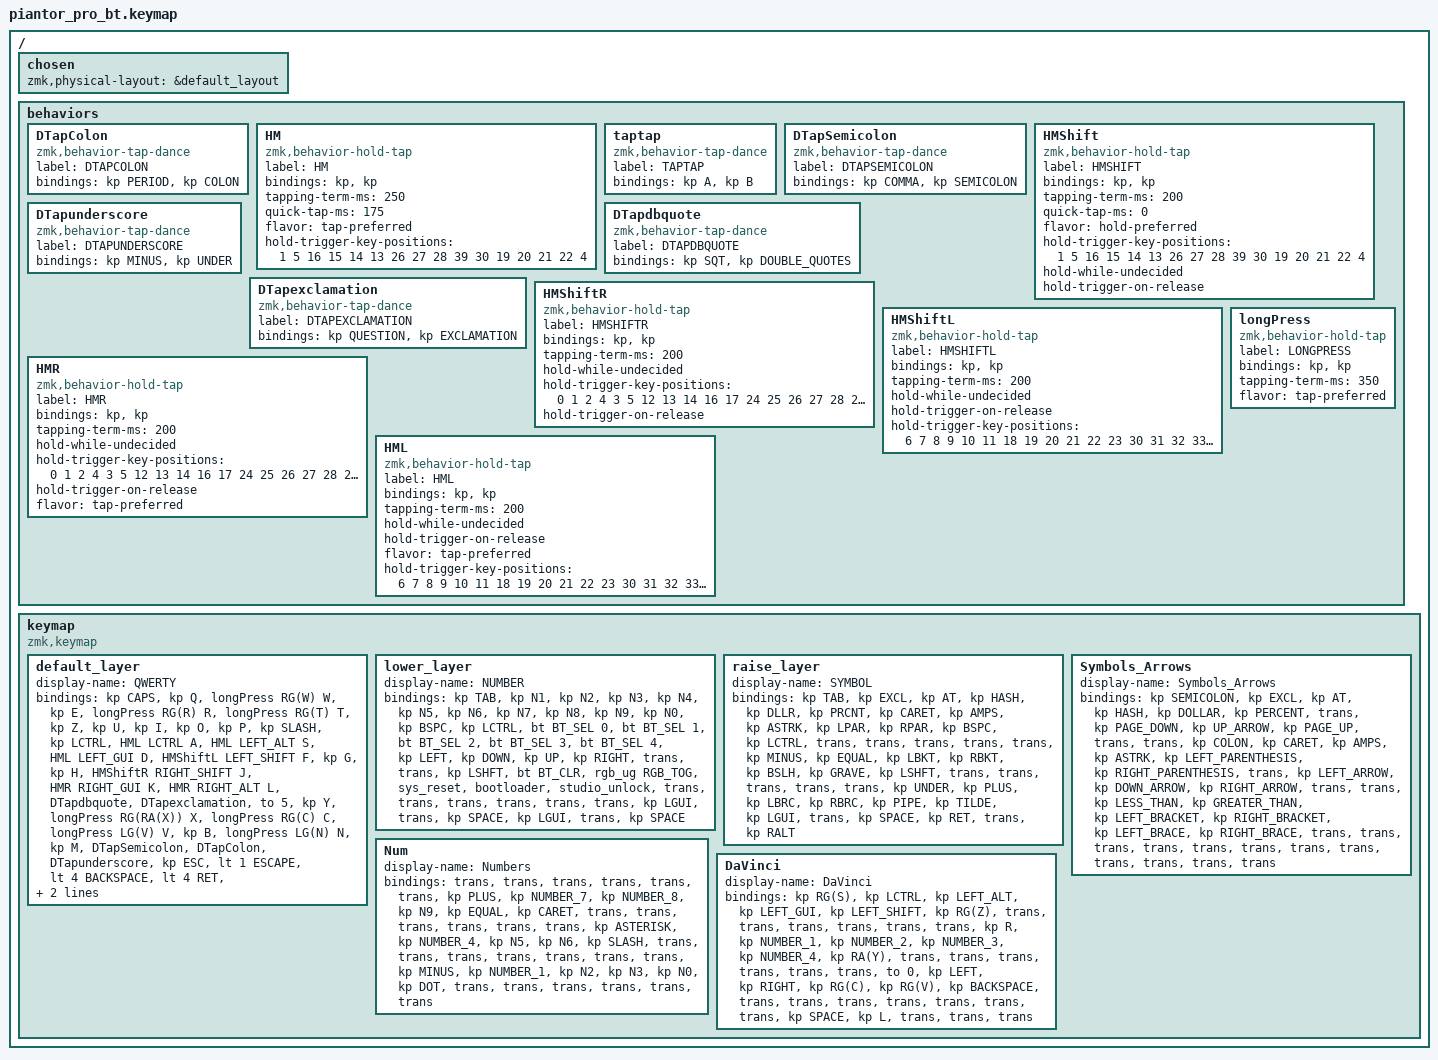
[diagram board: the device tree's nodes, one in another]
/*
 * Copyright (c) 2020 The ZMK Contributors
 *
 * SPDX-License-Identifier: MIT
 */

#include <behaviors.dtsi>
#include <dt-bindings/zmk/bt.h>
#include <dt-bindings/zmk/keys.h>
#include <dt-bindings/zmk/rgb.h>

/ {
    chosen { zmk,physical-layout = &default_layout; };
};

/ {
    behaviors {
        DTapColon: DTapColon {
            compatible = "zmk,behavior-tap-dance";
            label = "DTAPCOLON";
            #binding-cells = <0>;
            bindings = <&kp PERIOD>, <&kp COLON>;
        };

        HM: HM {
            compatible = "zmk,behavior-hold-tap";
            label = "HM";
            bindings = <&kp>, <&kp>;

            #binding-cells = <2>;
            tapping-term-ms = <250>;
            quick-tap-ms = <175>;
            flavor = "tap-preferred";
            hold-trigger-key-positions = <1 5 16 15 14 13 26 27 28 39 30 19 20 21 22 4>;
        };

        taptap: taptap {
            compatible = "zmk,behavior-tap-dance";
            label = "TAPTAP";
            #binding-cells = <0>;
            bindings = <&kp A>, <&kp B>;
        };

        DTapSemicolon: DTapSemicolon {
            compatible = "zmk,behavior-tap-dance";
            label = "DTAPSEMICOLON";
            #binding-cells = <0>;
            bindings = <&kp COMMA>, <&kp SEMICOLON>;
        };

        HMShift: HMShift {
            compatible = "zmk,behavior-hold-tap";
            label = "HMSHIFT";
            bindings = <&kp>, <&kp>;

            #binding-cells = <2>;
            tapping-term-ms = <200>;
            quick-tap-ms = <0>;
            flavor = "hold-preferred";
            hold-trigger-key-positions = <1 5 16 15 14 13 26 27 28 39 30 19 20 21 22 4>;
            hold-while-undecided;
            hold-trigger-on-release;
        };

        DTapdbquote: DTapdbquote {
            compatible = "zmk,behavior-tap-dance";
            label = "DTAPDBQUOTE";
            #binding-cells = <0>;
            bindings = <&kp SQT>, <&kp DOUBLE_QUOTES>;
        };

        DTapunderscore: DTapunderscore {
            compatible = "zmk,behavior-tap-dance";
            label = "DTAPUNDERSCORE";
            #binding-cells = <0>;
            bindings = <&kp MINUS>, <&kp UNDER>;
        };

        DTapexclamation: DTapexclamation {
            compatible = "zmk,behavior-tap-dance";
            label = "DTAPEXCLAMATION";
            #binding-cells = <0>;
            bindings = <&kp QUESTION>, <&kp EXCLAMATION>;
        };

        HMShiftR: HMShiftR {
            compatible = "zmk,behavior-hold-tap";
            label = "HMSHIFTR";
            bindings = <&kp>, <&kp>;

            #binding-cells = <2>;
            tapping-term-ms = <200>;
            hold-while-undecided;
            hold-trigger-key-positions = <0 1 2 4 3 5 12 13 14 16 17 24 25 26 27 28 29 36 37 38 15>;
            hold-trigger-on-release;
        };

        HMShiftL: HMShiftL {
            compatible = "zmk,behavior-hold-tap";
            label = "HMSHIFTL";
            bindings = <&kp>, <&kp>;

            #binding-cells = <2>;
            tapping-term-ms = <200>;
            hold-while-undecided;
            hold-trigger-on-release;
            hold-trigger-key-positions = <6 7 8 9 10 11 18 19 20 21 22 23 30 31 32 33 34 35 39 40 41>;
        };

        HMR: HMR {
            compatible = "zmk,behavior-hold-tap";
            label = "HMR";
            bindings = <&kp>, <&kp>;

            #binding-cells = <2>;
            tapping-term-ms = <200>;
            hold-while-undecided;
            hold-trigger-key-positions = <0 1 2 4 3 5 12 13 14 16 17 24 25 26 27 28 29 36 37 38 15>;
            hold-trigger-on-release;
            flavor = "tap-preferred";
        };

        HML: HML {
            compatible = "zmk,behavior-hold-tap";
            label = "HML";
            bindings = <&kp>, <&kp>;

            #binding-cells = <2>;
            tapping-term-ms = <200>;
            hold-while-undecided;
            hold-trigger-on-release;
            flavor = "tap-preferred";
            hold-trigger-key-positions = <6 7 8 9 10 11 18 19 20 21 22 23 30 31 32 33 34 35 39 40 41>;
        };

        longPress: longPress {
            compatible = "zmk,behavior-hold-tap";
            label = "LONGPRESS";
            bindings = <&kp>, <&kp>;

            #binding-cells = <2>;
            tapping-term-ms = <350>;
            flavor = "tap-preferred";
        };
    };

    keymap {
        compatible = "zmk,keymap";

        default_layer {
            display-name = "QWERTY";

            // --------------------------------------------------------------------------------
            // |  TAB |  Q  |  W  |  E  |  R  |  T  |  Y  |  U   |  I  |  O  |  P  | BSPC |
            // | CTRL |  A  |  S  |  D  |  F  |  G  |  H  |  J   |  K  |  L  |  ;  |  '   |
            // | SHFT |  Z  |  X  |  C  |  V  |  B  |  N  |  M   |  ,  |  .  |  /  | ESC  |
            //                    | GUI | LWR | SPC | ENT | RSE  | ALT |

            bindings = <
&kp CAPS  &kp Q  &longPress RG(W) W  &kp E  &longPress RG(R) R  &longPress RG(T) T  &kp Z  &kp U  &kp I  &kp O  &kp P  &kp SLASH  &kp LCTRL  &HML LCTRL A  &HML LEFT_ALT S  &HML LEFT_GUI D  &HMShiftL LEFT_SHIFT F  &kp G  &kp H  &HMShiftR RIGHT_SHIFT J  &HMR RIGHT_GUI K  &HMR RIGHT_ALT L  &DTapdbquote  &DTapexclamation  &to 5  &kp Y  &longPress RG(RA(X)) X  &longPress RG(C) C  &longPress LG(V) V  &kp B  &longPress LG(N) N  &kp M  &DTapSemicolon  &DTapColon  &DTapunderscore  &kp ESC  &lt 1 ESCAPE  &lt 4 BACKSPACE  &lt 4 RET  &longPress RIGHT_COMMAND TAB  &lt 3 SPACE  &kp LC(UP_ARROW)
            >;
        };

        lower_layer {
            display-name = "NUMBER";

            // -----------------------------------------------------------------------------------------
            // |  TAB |  1  |  2  |  3  |  4  |  5    |  6  |  7  |  8  |  9  |  0  | BSPC |
            // | CTRL | BT1 | BT2 | BT3 | BT4 | BT5   | LFT | DWN |  UP | RGT |     |      |
            // | SHFT | BTCR| RGB | RST | BOOT| Unlock|     |     |     |     |     |      |
            //                    | GUI |     | SPC   | ENT |     | ALT |

            bindings = <
&kp TAB  &kp N1  &kp N2  &kp N3  &kp N4  &kp N5  &kp N6  &kp N7  &kp N8  &kp N9  &kp N0  &kp BSPC  &kp LCTRL  &bt BT_SEL 0  &bt BT_SEL 1  &bt BT_SEL 2  &bt BT_SEL 3  &bt BT_SEL 4  &kp LEFT  &kp DOWN  &kp UP  &kp RIGHT  &trans  &trans  &kp LSHFT  &bt BT_CLR  &rgb_ug RGB_TOG  &sys_reset  &bootloader  &studio_unlock  &trans  &trans  &trans  &trans  &trans  &trans  &kp LGUI  &trans  &kp SPACE  &kp LGUI  &trans  &kp SPACE
            >;
        };

        raise_layer {
            display-name = "SYMBOL";

            // -----------------------------------------------------------------------------------------
            // |  TAB |  !  |  @  |  #  |  $  |  %  |  ^  |  &  |  *  |  (  |  )  | BSPC |
            // | CTRL |     |     |     |     |     |  -  |  =  |  [  |  ]  |  \  |  `   |
            // | SHFT |     |     |     |     |     |  _  |  +  |  {  |  }  | "|" |  ~   |
            //                    | GUI |     | SPC | ENT |     | ALT |

            bindings = <
&kp TAB  &kp EXCL  &kp AT  &kp HASH  &kp DLLR  &kp PRCNT  &kp CARET  &kp AMPS  &kp ASTRK  &kp LPAR  &kp RPAR  &kp BSPC  &kp LCTRL  &trans  &trans  &trans  &trans  &trans  &kp MINUS  &kp EQUAL  &kp LBKT  &kp RBKT  &kp BSLH  &kp GRAVE  &kp LSHFT  &trans  &trans  &trans  &trans  &trans  &kp UNDER  &kp PLUS  &kp LBRC  &kp RBRC  &kp PIPE  &kp TILDE  &kp LGUI  &trans  &kp SPACE  &kp RET  &trans  &kp RALT
            >;
        };

        Symbols_Arrows {
            display-name = "Symbols_Arrows";
            bindings = <
&kp SEMICOLON  &kp EXCL  &kp AT  &kp HASH  &kp DOLLAR  &kp PERCENT  &trans  &kp PAGE_DOWN  &kp UP_ARROW  &kp PAGE_UP  &trans  &trans  &kp COLON  &kp CARET  &kp AMPS  &kp ASTRK  &kp LEFT_PARENTHESIS  &kp RIGHT_PARENTHESIS  &trans  &kp LEFT_ARROW  &kp DOWN_ARROW  &kp RIGHT_ARROW  &trans  &trans  &kp LESS_THAN  &kp GREATER_THAN  &kp LEFT_BRACKET  &kp RIGHT_BRACKET  &kp LEFT_BRACE  &kp RIGHT_BRACE  &trans  &trans  &trans  &trans  &trans  &trans  &trans  &trans  &trans  &trans  &trans  &trans
            >;
        };

        Num {
            display-name = "Numbers";
            bindings = <
&trans  &trans  &trans  &trans  &trans  &trans  &kp PLUS  &kp NUMBER_7  &kp NUMBER_8  &kp N9  &kp EQUAL  &kp CARET  &trans  &trans  &trans  &trans  &trans  &trans  &kp ASTERISK  &kp NUMBER_4  &kp N5  &kp N6  &kp SLASH  &trans  &trans  &trans  &trans  &trans  &trans  &trans  &kp MINUS  &kp NUMBER_1  &kp N2  &kp N3  &kp N0  &kp DOT  &trans  &trans  &trans  &trans  &trans  &trans
            >;
        };

        DaVinci {
            display-name = "DaVinci";
            bindings = <
&kp RG(S)  &kp LCTRL  &kp LEFT_ALT  &kp LEFT_GUI  &kp LEFT_SHIFT  &kp RG(Z)  &trans  &trans  &trans  &trans  &trans  &trans  &kp R  &kp NUMBER_1  &kp NUMBER_2  &kp NUMBER_3  &kp NUMBER_4  &kp RA(Y)  &trans  &trans  &trans  &trans  &trans  &trans  &to 0  &kp LEFT  &kp RIGHT  &kp RG(C)  &kp RG(V)  &kp BACKSPACE  &trans  &trans  &trans  &trans  &trans  &trans  &trans  &kp SPACE  &kp L  &trans  &trans  &trans
            >;
        };
    };
};
